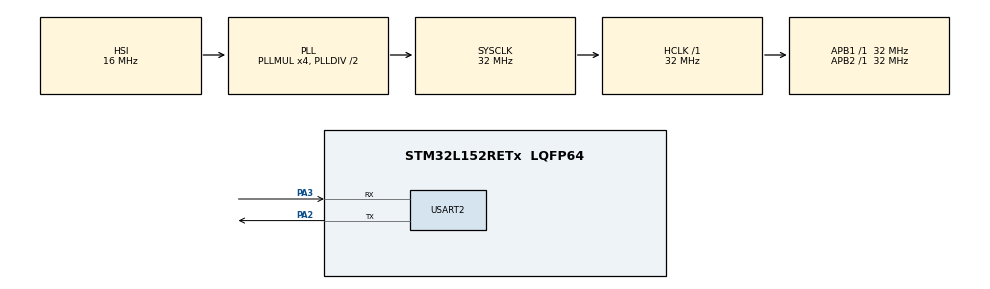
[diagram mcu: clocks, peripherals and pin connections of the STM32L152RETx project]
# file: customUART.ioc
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Mcu.Family=STM32L1
Mcu.Name=STM32L152RETx
Mcu.Package=LQFP64
NVIC.PriorityGroup=NVIC_PRIORITYGROUP_4
NVIC.USART2_IRQn=true\:0\:0\:false\:false\:true\:true\:true
PA13.Mode=Serial_Wire
PA13.Signal=SYS_JTMS-SWDIO
PA14.Mode=Serial_Wire
PA14.Signal=SYS_JTCK-SWCLK
PA2.Mode=Asynchronous
PA2.Signal=USART2_TX
PA3.Mode=Asynchronous
PA3.Signal=USART2_RX
ProjectManager.HeapSize=0x200
ProjectManager.StackSize=0x400
ProjectManager.TargetToolchain=MDK-ARM V5.27
RCC.48MHZClocksFreq_Value=32000000
RCC.AHBFreq_Value=32000000
RCC.APB1Freq_Value=32000000
RCC.APB1TimFreq_Value=32000000
RCC.APB2Freq_Value=32000000
RCC.APB2TimFreq_Value=32000000
RCC.HCLKFreq_Value=32000000
RCC.HSE_VALUE=24000000
RCC.HSI_VALUE=16000000
RCC.LSE_VALUE=32768
RCC.MSI_VALUE=2097000
RCC.PLLMUL=RCC_PLL_MUL4
RCC.SYSCLKFreq_VALUE=32000000
RCC.SYSCLKSource=RCC_SYSCLKSOURCE_PLLCLK
RCC.VCOOutputFreq_Value=64000000
USART2.VirtualMode=VM_ASYNC
board=custom

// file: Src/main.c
/* USER CODE BEGIN Header */
/**
  ******************************************************************************
  * @file           : main.c
  * @brief          : Main program body
  ******************************************************************************
  * @attention
  *
  * <h2><center>&copy; Copyright (c) 2022 STMicroelectronics.
  * All rights reserved.</center></h2>
  *
  * This software component is licensed by ST under BSD 3-Clause license,
  * the "License"; You may not use this file except in compliance with the
  * License. You may obtain a copy of the License at:
  *                        opensource.org/licenses/BSD-3-Clause
  *
  ******************************************************************************
  */
/* USER CODE END Header */

#include "main.h"

/* USER CODE BEGIN Includes */
#include "cus_uart.h"
#include "response_ci.h"
/* USER CODE END Includes */

UART_HandleTypeDef huart2;

void SystemClock_Config(void);
static void MX_GPIO_Init(void);
static void MX_USART2_UART_Init(void);

/* USER CODE BEGIN 0 */
static uint8_t data_rx;
void HAL_UART_RxCpltCallback(UART_HandleTypeDef *huart){
	if(huart->Instance == huart2.Instance){
    receive_data(data_rx);
    HAL_UART_Receive_IT(&huart2, &data_rx,1);
	}
}
/* USER CODE END 0 */

int main(void)
{

  /* MCU Configuration--------------------------------------------------------*/

  /* Reset of all peripherals, Initializes the Flash interface and the Systick. */
  HAL_Init();

  /* Configure the system clock */
  SystemClock_Config();

  /* Initialize all configured peripherals */
  MX_GPIO_Init();
  MX_USART2_UART_Init();
  /* USER CODE BEGIN 2 */
	HAL_UART_Receive_IT(&huart2, &data_rx, 1);
  response_init(&huart2);
  /* USER CODE END 2 */

  /* Infinite loop */
  while (1)
  {

    /* USER CODE BEGIN 3 */
    uart_handle();
  }
  /* USER CODE END 3 */
}

void SystemClock_Config(void)
{
  RCC_OscInitTypeDef RCC_OscInitStruct = {0};
  RCC_ClkInitTypeDef RCC_ClkInitStruct = {0};

  /** Configure the main internal regulator output voltage
  */
  __HAL_PWR_VOLTAGESCALING_CONFIG(PWR_REGULATOR_VOLTAGE_SCALE1);
  /** Initializes the CPU, AHB and APB busses clocks
  */
  RCC_OscInitStruct.OscillatorType = RCC_OSCILLATORTYPE_HSI;
  RCC_OscInitStruct.HSIState = RCC_HSI_ON;
  RCC_OscInitStruct.HSICalibrationValue = RCC_HSICALIBRATION_DEFAULT;
  RCC_OscInitStruct.PLL.PLLState = RCC_PLL_ON;
  RCC_OscInitStruct.PLL.PLLSource = RCC_PLLSOURCE_HSI;
  RCC_OscInitStruct.PLL.PLLMUL = RCC_PLL_MUL4;
  RCC_OscInitStruct.PLL.PLLDIV = RCC_PLL_DIV2;
  if (HAL_RCC_OscConfig(&RCC_OscInitStruct) != HAL_OK)
  {
    Error_Handler();
  }
  /** Initializes the CPU, AHB and APB busses clocks
  */
  RCC_ClkInitStruct.ClockType = RCC_CLOCKTYPE_HCLK|RCC_CLOCKTYPE_SYSCLK
                              |RCC_CLOCKTYPE_PCLK1|RCC_CLOCKTYPE_PCLK2;
  RCC_ClkInitStruct.SYSCLKSource = RCC_SYSCLKSOURCE_PLLCLK;
  RCC_ClkInitStruct.AHBCLKDivider = RCC_SYSCLK_DIV1;
  RCC_ClkInitStruct.APB1CLKDivider = RCC_HCLK_DIV1;
  RCC_ClkInitStruct.APB2CLKDivider = RCC_HCLK_DIV1;

  if (HAL_RCC_ClockConfig(&RCC_ClkInitStruct, FLASH_LATENCY_1) != HAL_OK)
  {
    Error_Handler();
  }
}

static void MX_USART2_UART_Init(void)
{

  huart2.Instance = USART2;
  huart2.Init.BaudRate = 115200;
  huart2.Init.WordLength = UART_WORDLENGTH_8B;
  huart2.Init.StopBits = UART_STOPBITS_1;
  huart2.Init.Parity = UART_PARITY_NONE;
  huart2.Init.Mode = UART_MODE_TX_RX;
  huart2.Init.HwFlowCtl = UART_HWCONTROL_NONE;
  huart2.Init.OverSampling = UART_OVERSAMPLING_16;
  if (HAL_UART_Init(&huart2) != HAL_OK)
  {
    Error_Handler();
  }

}

static void MX_GPIO_Init(void)
{

  /* GPIO Ports Clock Enable */
  __HAL_RCC_GPIOA_CLK_ENABLE();

}

void Error_Handler(void)
{
}

/************************ (C) COPYRIGHT STMicroelectronics *****END OF FILE****/
